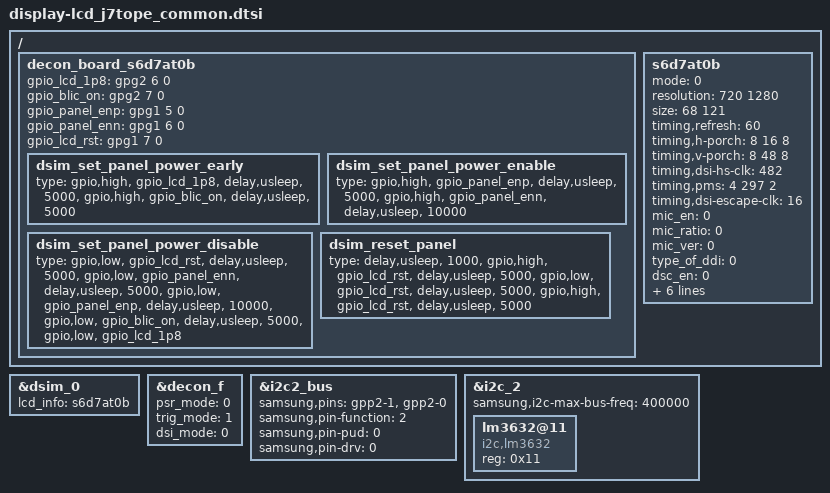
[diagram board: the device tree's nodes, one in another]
/*
 * SAMSUNG LCD Panel Device Tree Source
 *
 * Copyright (c) Samsung Electronics Co., Ltd.
 *		http://www.samsung.com
 *
 * This program is free software; you can redistribute it and/or modify
 * it under the terms of the GNU General Public License version 2 as
 * published by the Free Software Foundation.
*/

/ {
	decon_board_s6d7at0b: decon_board_s6d7at0b {
		gpio_lcd_1p8 = <&gpg2 6 0>;
		gpio_blic_on = <&gpg2 7 0>;
		gpio_panel_enp = <&gpg1 5 0>;
		gpio_panel_enn = <&gpg1 6 0>;
		gpio_lcd_rst = <&gpg1 7 0>;

		dsim_set_panel_power_early {
			type =
			"gpio,high",	"gpio_lcd_1p8",
			"delay,usleep",	"5000",
			"gpio,high",	"gpio_blic_on",
			"delay,usleep",	"5000";
		};
		dsim_set_panel_power_enable {
			type =
			"gpio,high",	"gpio_panel_enp",
			"delay,usleep",	"5000",
			"gpio,high",	"gpio_panel_enn",
			"delay,usleep",	"10000";
		};
		dsim_set_panel_power_disable {
			type =
			"gpio,low",	"gpio_lcd_rst",
			"delay,usleep",	"5000",
			"gpio,low",	"gpio_panel_enn",
			"delay,usleep",	"5000",
			"gpio,low",	"gpio_panel_enp",
			"delay,usleep",	"10000",
			"gpio,low",	"gpio_blic_on",
			"delay,usleep",	"5000",
			"gpio,low",	"gpio_lcd_1p8";
		};
		dsim_reset_panel {
			type =
			"delay,usleep",	"1000",
			"gpio,high",	"gpio_lcd_rst",
			"delay,usleep",	"5000",
			"gpio,low",	"gpio_lcd_rst",
			"delay,usleep",	"5000",
			"gpio,high",	"gpio_lcd_rst",
			"delay,usleep",	"5000";
		};
	};

	s6d7at0b: s6d7at0b {
		mode = <0>; /* 0: video mode, 1: DP command mode, 2: MIPI command mode */
		resolution = <720 1280>;
		size = <68 121>;
		timing,refresh = <60>;
		timing,h-porch = <8 16 8>;
		timing,v-porch = <8 48 8>;
		timing,dsi-hs-clk = <482>;
		timing,pms = <4 297 2>;
		timing,dsi-escape-clk = <16>;
		mic_en = <0>;		/* 0: Disable, 1: Enable */
		mic_ratio = <0>;	/* 0: 1/2 mic, 1: 1/3 mic */
		mic_ver = <0>;		/* 0: mic v1.1, 1: v1.2, 2: v2.0 */
		type_of_ddi = <0>;	/* 0: Samsung Mobile, 1: MAGNA, 2: Normal(Etc) */
		dsc_en = <0>;		/* 0: Disable, 1: Enable */
		dsc_cnt = <0>;		/* used DSC count */
		dsc_slice_num = <0>;	/* count of dsc slice */
		data_lane = <4>;	/* number of using data lane */
		vt_compensation = <742>;	/* for difference between wordclk and vclk at video mode */
		clklane_onoff = <1>;
		decon_board = <&decon_board_s6d7at0b>;
	};
};

&dsim_0 {
	lcd_info = <&s6d7at0b>;
};

&decon_f {
	psr_mode = <0>;		/* 0: video mode, 1: DP command mode, 2: MIPI command mode */
	trig_mode = <1>;	/* 0: hw trigger, 1: sw trigger */
	dsi_mode = <0>;		/* 0: single dsi, 1: dual dsi */
};

/* pinctrl_3: pinctrl@139B0000 */
&i2c2_bus {
	samsung,pins = "gpp2-1", "gpp2-0";
	samsung,pin-function = <2>;
	samsung,pin-pud = <0>;
	samsung,pin-drv = <0>;
};

/* i2c_2: i2c@13850000 */
&i2c_2 {
	status = "okay";
	samsung,i2c-max-bus-freq = <400000>;

	lm3632@11 {
		compatible = "i2c,lm3632";
		reg = <0x11>;
	};
};

